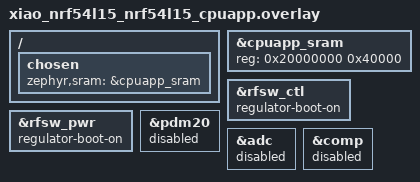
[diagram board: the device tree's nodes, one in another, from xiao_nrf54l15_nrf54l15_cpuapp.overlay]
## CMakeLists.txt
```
cmake_minimum_required(VERSION 3.20.0)
find_package(Zephyr REQUIRED HINTS $ENV{ZEPHYR_BASE})

project(Garage)

target_sources(app PRIVATE src/main.cpp ../src/blinker.cpp src/ble_initiator.cpp ../src/PairingConfig.cpp)
```

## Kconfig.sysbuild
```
#
# Copyright (c) 2025 Nordic Semiconductor
#
# SPDX-License-Identifier: LicenseRef-Nordic-5-Clause
#

source "share/sysbuild/Kconfig"

config NRF_DEFAULT_IPC_RADIO
	default y

config NETCORE_IPC_RADIO_BT_HCI_IPC
	default y
```

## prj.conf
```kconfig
#
# Copyright (c) 2024 Nordic Semiconductor ASA
#
# SPDX-License-Identifier: LicenseRef-Nordic-5-Clause
#

# Minimal config for Xiao nRF54L15 (no external memory)
CONFIG_GPIO=y
CONFIG_REBOOT=y

# Force SoftDevice Controller only (disable Zephyr controller)
CONFIG_BT_LL_SW_SPLIT=n

CONFIG_BT=y
CONFIG_BT_SMP=y
CONFIG_BT_CENTRAL=y
CONFIG_BT_BROADCASTER=y
CONFIG_BT_MAX_CONN=5
CONFIG_BT_MAX_PAIRED=5
CONFIG_BT_BONDABLE=y
CONFIG_BT_DEVICE_NAME="Garage_Ranger"

CONFIG_BT_GATT_CLIENT=y
CONFIG_BT_GATT_DYNAMIC_DB=y

CONFIG_BT_CHANNEL_SOUNDING=y
CONFIG_BT_RAS=y
CONFIG_BT_RAS_RREQ=y

CONFIG_BT_SCAN=y
CONFIG_BT_SCAN_FILTER_ENABLE=y
CONFIG_BT_SCAN_UUID_CNT=5

# The Ranging Profile recommends a MTU of at least 247 octets.
CONFIG_BT_L2CAP_TX_MTU=498
CONFIG_BT_BUF_ACL_TX_SIZE=502
CONFIG_BT_BUF_ACL_RX_SIZE=502
CONFIG_BT_ATT_PREPARE_COUNT=5
CONFIG_BT_CTLR_DATA_LENGTH_MAX=251

# Single antenna configuration for Xiao nRF54L15
CONFIG_BT_RAS_MAX_ANTENNA_PATHS=1
CONFIG_BT_CTLR_SDC_CS_ROLE_INITIATOR_ONLY=y

# Disabling the CS Test command reduces flash usage
CONFIG_BT_CTLR_CHANNEL_SOUNDING_TEST=n

# This allows CS and ACL to use different PHYs
CONFIG_BT_TRANSMIT_POWER_CONTROL=y

# This improves the performance of floating-point operations
CONFIG_FPU=y
CONFIG_FPU_SHARING=y

CONFIG_CBPRINTF_FP_SUPPORT=y

CONFIG_BT_CS_DE=y
CONFIG_BT_CS_DE_512_NFFT=y

# Console and logging
CONFIG_SERIAL=y
CONFIG_CONSOLE=y
CONFIG_UART_CONSOLE=y
CONFIG_LOG=y
CONFIG_LOG_MODE_IMMEDIATE=y
CONFIG_LOG_DEFAULT_LEVEL=3


# Enable Bluetooth Settings (Persistent Storage)
CONFIG_BT_SETTINGS=y

# Enable Flash and NVS (Non-Volatile Storage)
CONFIG_FLASH=y
CONFIG_FLASH_PAGE_LAYOUT=y
CONFIG_FLASH_MAP=y
CONFIG_NVS=y
CONFIG_SETTINGS=y
CONFIG_SETTINGS_NVS=y

# On nRF54L, crypto is handled via the PSA driver automatically
# We just need to ensure the stack has enough headroom
CONFIG_BT_L2CAP_TX_BUF_COUNT=20

# Increase memory for the pairing process (The "ENOMEM" fix)
# CONFIG_BT_BUF_SYS_TX_COUNT=15
CONFIG_BT_CONN_TX_MAX=10

# Thread stack sizes - Security Level 3/4 requires more stack
CONFIG_BT_RX_STACK_SIZE=2200
CONFIG_BT_HCI_TX_STACK_SIZE=1024
CONFIG_SYSTEM_WORKQUEUE_STACK_SIZE=2048

# Make HCI and security errors human-readable in logs
CONFIG_BT_HCI_ERR_TO_STR=y
CONFIG_BT_SECURITY_ERR_TO_STR=y
```

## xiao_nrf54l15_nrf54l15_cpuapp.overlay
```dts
/*
 * Copyright (c) 2025 Nordic Semiconductor ASA
 *
 * SPDX-License-Identifier: LicenseRef-Nordic-5-Clause
 */

/ {
    chosen {
        /* Allocate full 256KB SRAM to cpuapp (no FLPR core used) */
        zephyr,sram = &cpuapp_sram;
    };
};

/* Override SRAM partition to use full 256KB */
&cpuapp_sram {
    reg = <0x20000000 0x40000>; /* 256KB at 0x20000000 */
};

&rfsw_ctl {
    regulator-boot-on;
};

&rfsw_pwr {
    regulator-boot-on;
};

&pdm20 {
    status = "disabled";
};

&adc {
    status = "disabled";
};

&comp {
    status = "disabled";
};
```

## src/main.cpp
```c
#include <stdio.h>
#include <zephyr/kernel.h>
#include <zephyr/sys/printk.h>
#include <zephyr/sys/reboot.h>

#include "../../src/blinker.h"
#include "ble_initiator.h"

#include <zephyr/logging/log.h>
LOG_MODULE_REGISTER(app_main, LOG_LEVEL_INF);

/* 1000 msec = 1 sec */
#define SLEEP_TIME_MS 2000
#define ON_TIME_MS 150
#define OFF_TIME_MS 100
#define REBOOT_TIME (60 * 60 * 12) // * SLEEP_TIME_MS = 24 hours.

static uint8_t loopCount = 0;

int main(void)
{
    LOG_INF("[main] Starting application\n");

    LOG_INF("[main] Initializing Blinker...\n");
    Blinker bl;
    bl.blink(2, ON_TIME_MS, OFF_TIME_MS);
    LOG_INF("[main] Blinker initialized\n");

    LOG_INF("[main] Initializing Bluetooth...\n");
    BleInitiator bleInitiator;
    bleInitiator.init();
    LOG_INF("[main] Bluetooth initialized\n");

    LOG_INF("[main] Requesting blink patterns\n");
    while (1)
    {
        if (bleInitiator.connected())
        {
            bl.blink(1, ON_TIME_MS * 2, OFF_TIME_MS);
        }
        else
        {
            bl.blink(2, ON_TIME_MS, OFF_TIME_MS);
        }

        if (loopCount++ > REBOOT_TIME)
        {
            LOG_INF("[main] Rebooting (cold) after %d loops", loopCount);
            sys_reboot(SYS_REBOOT_COLD);
        }
        k_msleep(SLEEP_TIME_MS);
    }
    return 0;
}
```

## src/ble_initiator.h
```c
// Lightweight C++ wrappers for Zephyr BLE Channel Sounding (initiator & reflector)
#ifndef BLE_INITIATOR_H
#define BLE_INITIATOR_H

#include <zephyr/bluetooth/conn.h>
/* Forward declarations for work and DM types used by handlers */
struct k_work;

class BleInitiator
{
public:
    // Initialize the initiator with an active connection for a given index (0 or 1)
    // Returns true on success
    bool init();
    bool connected();

private:
    // Enable and configure radio hardware and Bluetooth stack.
    // Returns true on success.
    bool enableRadio();
    // Initialize and start BLE scanning. Returns true on success.
    bool startScan();
    // configure the RAS and ChannelSounding
    bool configureRasCs();
    bool configureRealtimeRas();
    bool configureChannelSounding();
    bool beginCsProcedure();
};

#endif
```
